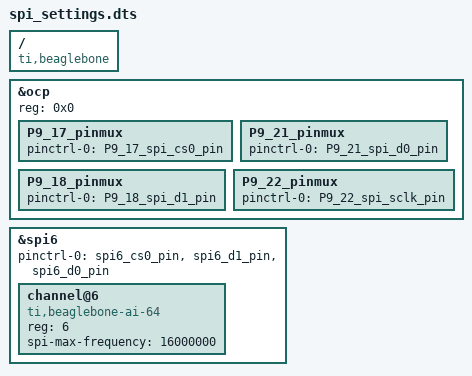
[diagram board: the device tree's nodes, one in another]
/dts-v1/;
/plugin/;

/ {
    compatible = "ti,beaglebone", "ti,beaglebone-ai-64";

    fragment@0 {
        target = <&ocp>;
        #address-cells = <1>;
        #size-cells = <0>;
        
        __overlay__ { 
            // overlay-name = "spi-overlay";
            reg = <0x0>;
            P9_17_pinmux {
                pinctrl-names = "default";
                pinctrl-0 = <&P9_17_spi_cs0_pin>;
            };

            P9_21_pinmux {
                pinctrl-names = "default";
                pinctrl-0 = <&P9_21_spi_d0_pin>;
            };

            P9_18_pinmux {
                pinctrl-names = "default";
                pinctrl-0 = <&P9_18_spi_d1_pin>;
            };

            P9_22_pinmux {
                pinctrl-names = "default";
                pinctrl-0 = <&P9_22_spi_sclk_pin>;
            };
            // channel@0 {
            //     reg = <0>;            // channel@0 {
            //     reg = <0>;
            //     compatible = "ti,beaglebone-ai-64";
            //     spi-max-frequency = <16000000>;
            // };
            //     compatible = "ti,beaglebone-ai-64";
            //     spi-max-frequency = <16000000>;
            // };
        };
    };

    // fragment@1 {
    //     target = <&spi1>;

    //     __overlay__ {
    //         status = "okay";
    //         pinctrl-names = "default";
    //         pinctrl-0 = <&spi1_clk_pin>;
    //         #address-cells = <1>;
    //         #size-cells = <0>;

    //         channel@1 {
    //             reg = <1>;
    //             compatible = "ti,beaglebone-ai-64";
    //             spi-max-frequency = <16000000>;
    //         };
    //     };
    // };

    fragment@1 {
        target = <&spi6>;

        __overlay__ {
            status = "okay";
            pinctrl-names = "default";
            pinctrl-0 = <&spi6_cs0_pin>, <&spi6_d1_pin>, <&spi6_d0_pin>;
            #address-cells = <1>;
            #size-cells = <0>;

            channel@6 {
                reg = <6>;
                compatible = "ti,beaglebone-ai-64";
                spi-max-frequency = <16000000>;
            };
        };
    };
};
